# apollo4l register map
Vendor: Ambiq Micro; Series: Apollo; File version: 1.0
CPU: CM4 r1p0, little endian, MPU, FPU, I-cache, D-cache, VTOR, ITCM, DTCM, 3 interrupt priority bits, 0 interrupts
Registers are 32-bit, read-write, reset 0x0 unless marked. A register's access mark holds for its fields unless they carry their own. Offsets are from the block's base; [hi:lo] are bit positions; lines under a group give offsets from that group; {n}, {i} and the like mark numbered series; 'fields as' and 'values as' point back to an identical list.

## PWRCTRL — PWR Controller Register Bank
Base 0x40021000
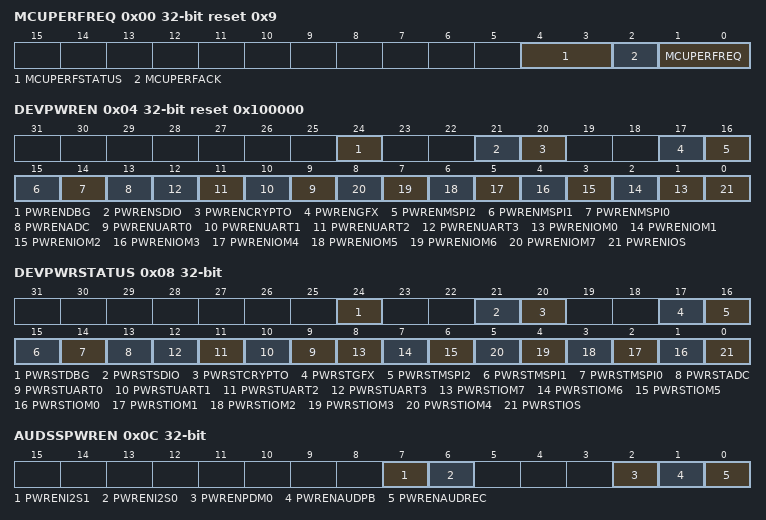
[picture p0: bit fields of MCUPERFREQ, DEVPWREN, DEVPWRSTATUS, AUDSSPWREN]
0x00 MCUPERFREQ reset 0x9 — This register provides the performance mode knobs for MCU. S/w should write the *PERFREQ field to desired mode and wait for the *PERFACK and check for the *PERFSTATUS. Some times system may not allow certain modes but *PERFACK should always follow *PERFREQ change.
  [4:3] MCUPERFSTATUS — MCU Performance mode request
    0=ULP (MCU is in ULP mode (freq=24MHz)); 1=LP (MCU is in LP mode (freq=96MHz)); 2=HP (MCU is in HP mode (freq=192MHz))
  [2] MCUPERFACK — Indicates the MCU performance status indicated in STATUS register is valid.
  [1:0] MCUPERFREQ — MCU Performance mode request
    0=ULP (MCU to be run in ULP mode (freq=24MHz)); 1=LP (MCU to be run in LP mode (freq=96MHz)); 2=HP (MCU to be run in HP mode (freq=192MHz))
0x04 DEVPWREN reset 0x100000 — This enables various peripherals power domains.
  [24] PWRENDBG — Powerup DBG power domain
    1=EN (Enable); 0=DIS (Disable)
  [21] PWRENSDIO — Power up SDIO controller
    1=EN (Power up SDIO); 0=DIS (Power down SDIO)
  [20] PWRENCRYPTO — Power up CRYPTO module
    1=EN (Power up CRYPTO); 0=DIS (Power down CRYPTO)
  [17] PWRENGFX — Power up GFX controller
    1=EN (Power up GFX); 0=DIS (Power down GFX)
  [16] PWRENMSPI2 — Power up MSPI Controller2
    1=EN (Power up MSPI2); 0=DIS (Power down MSPI2)
  [15] PWRENMSPI1 — Power up MSPI Controller1
    1=EN (Power up MSPI1); 0=DIS (Power down MSPI1)
  [14] PWRENMSPI0 — Power up MSPI Controller0
    1=EN (Power up MSPI0); 0=DIS (Power down MSPI0)
  [13] PWRENADC — Power up ADC Digital Controller
    1=EN (Power up ADC); 0=DIS (Power Down ADC)
  [n+9] PWRENUART{n} (n=0..3) — Power up UART Controller {n}
    1=EN (Power up UART {n}); 0=DIS (Power down UART {n})
  [n+1] PWRENIOM{n} (n=0..7) — Power up IO Master {n}
    1=EN (Power up IO Master {n}); 0=DIS (Power down IO Master {n})
  [0] PWRENIOS — Power up IO Slave
    1=EN (Power up IO slave); 0=DIS (Power down IO slave)
0x08 DEVPWRSTATUS — This provides the power status for the peripheral device domains controlled through DEVPWREN register. Value of 1 means the device is powred up and ready to be used and 0 means its not powered up.
  [all] fields
    1=ON (Domain powered on); 0=OFF (Domain powered off)
  [24] PWRSTDBG — Power Status DBG subsystem
  [21] PWRSTSDIO — Power Status SDIO controller
  [20] PWRSTCRYPTO — Power Status CRYPTO module
  [17] PWRSTGFX — Power Status GFX controller
  [16] PWRSTMSPI2 — Power Status MSPI Controller2
  [15] PWRSTMSPI1 — Power Status MSPI Controller1
  [14] PWRSTMSPI0 — Power Status MSPI Controller0
  [13] PWRSTADC — Power Status ADC Digital Controller
  [n+9] PWRSTUART{n} (n=0..3) — Power Status UART Controller {n}
  [8] PWRSTIOM7 — Power Status IO Master 7
  [7] PWRSTIOM6 — Power Status IO Master 6
  [6] PWRSTIOM5 — Power Status IO Master 5
  [n+1] PWRSTIOM{n} (n=0..4) — Power status IO Master {n}
  [0] PWRSTIOS — Power status IO Slave
0x0C AUDSSPWREN — This enables various power domains in audio subsystem.
  [7] PWRENI2S1 — Power up audio subsystem legacy I2S1 domain. I2S1 domain must be disabled. I2S1 is not available in Apoll4L.
    1=EN (Power up I2S1); 0=DIS (Power down I2S1)
  [6] PWRENI2S0 — Power up audio subsystem I2S0 domain
    1=EN (Power up I2S0); 0=DIS (Power down I2S0)
  [2] PWRENPDM0 — Power up audio subsystem PDM0 domain
    1=EN (Power up PDM0); 0=DIS (Power down PDM0)
  [1] PWRENAUDPB — Power up Audio Playback
    1=EN (Power up AUDPB); 0=DIS (Power down AUDPB)
  [0] PWRENAUDREC — Power up Audio Record
    1=EN (Power up AUDREC); 0=DIS (Power down AUDREC)
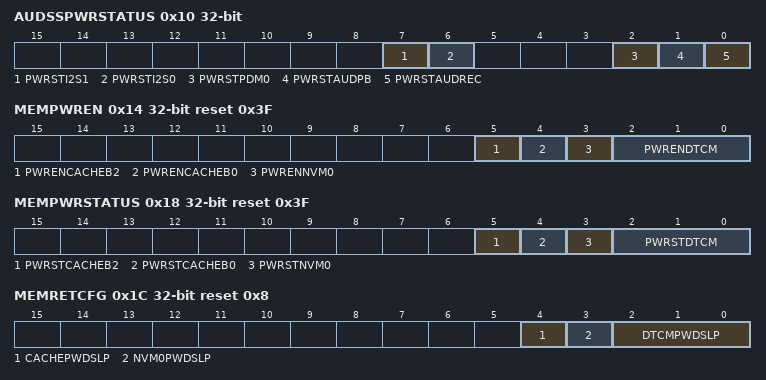
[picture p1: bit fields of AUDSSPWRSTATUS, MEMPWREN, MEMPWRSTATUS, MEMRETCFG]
0x10 AUDSSPWRSTATUS — This provides the power status for the peripheral domains controlled through AUDSSPWREN register. Value of 1 means the device is powred up and ready to be used and 0 means its not powered up.
  [all] fields
    1=ON (Domain powered on); 0=OFF (Domain powered off)
  [7] PWRSTI2S1 — Power Status audio subsystem legacy I2S1 domain. I2S1 is not available in Apoll4L.
  [6] PWRSTI2S0 — Power Status audio subsystem I2S0 domain
  [2] PWRSTPDM0 — Power Status audio subsystem PDM0 domain
  [1] PWRSTAUDPB — Power Status Audio Playback block
  [0] PWRSTAUDREC — Power Status Audio Record block
0x14 MEMPWREN reset 0x3F — This register enables the individual banks for the memories. When set, power will be enabled to the banks. This register works in conjunction with the MEMRETCFG register. If this register is not set, then power will always be disabled to the memory bank.
  [5] PWRENCACHEB2 — Power up Cache Bank 2. This works in conjunction with Cache enable from flash_cache module. To power up cache bank2, cache has to be enabled and this bit has to be set.
    1=EN (Power up Cache Bank 2); 0=DIS (Power down Cache Bank 2)
  [4] PWRENCACHEB0 — Power up Cache Bank 0. This works in conjunction with Cache enable from flash_cache module. To power up cache bank0, cache has to be enabled and this bit has to be set.
    1=EN (Power up Cache Bank 0); 0=DIS (Power down Cache Bank 0)
  [3] PWRENNVM0 — Power up NVM0
    1=EN (Power up NVM0); 0=DIS (Power down NVM0)
  [2:0] PWRENDTCM — Power up DTCM
    0=NONE (Do not enable power to any DTCMs); 1=TCM32K (Power ON only lower 32k); 3=TCM128K (Power ON only lower 128k); 7=TCM384K (Power ON 384k)
0x18 MEMPWRSTATUS reset 0x3F — It provides the power status for all the memory banks including- caches, nvm (0 and 1) and all the SRAM groups. The status here should reflect the enable provided by the MEMPWREN register. There may be a lag time between setting the bits in MEMPWREN register and MEMPWRSTATUS register, due to the need to cycle the power gate and isolation seqeunces to the memory banks.
  [5] PWRSTCACHEB2 — This bit is 1 if power is supplied to Cache Bank 2
  [4] PWRSTCACHEB0 — This bit is 1 if power is supplied to Cache Bank 0
  [3] PWRSTNVM0 — This bit is 1 if power is supplied to NVM 0
  [2:0] PWRSTDTCM — Power status for DTCM. Each bit corresponds to one of the TCMs. bit0=DTCM0_0, bit1=DTCM0_1, bit2=DTCM1.
    0=NONE (Do not enable power to any DTCMs); 1=TCM32K (Only lower 32k is powered up); 3=TCM128K (Only lower 128k is powered up); 7=TCM384K (All 384k is powered up)
0x1C MEMRETCFG reset 0x8 — This controls the power down of the SRAM banks in deep sleep mode. If this is set, then the power for that SRAM bank will be gated when the core goes into deep sleep. Upon wake, the data within the SRAMs will be erased. If this is not set, retention voltage will be applied to the SRAM bank when the core goes into deep sleep. Upon wake, the data within the SRAMs are retained. Do not set this if the SRAM bank is used as the target for DMA transfer while CPU in deepsleep.
  [4] CACHEPWDSLP — power down cache in deep sleep
    1=EN (Power down cache in deep sleep); 0=DIS (Retain cache in deep sleep)
  [3] NVM0PWDSLP — Powerdown NVM0 in deep sleep
    1=EN (NVM0 is powered down during deepsleep); 0=DIS (NVM0 is kept powered on during deepsleep)
  [2:0] DTCMPWDSLP — power down DTCM in deep sleep
    0=NONE (All DTCM retained); 1=GROUP0DTCM0 (Group0_DTCM0 powered down in deep sleep (0KB-32KB)); 2=GROUP0DTCM1 (Group0_DTCM1 powered down in deep sleep (32KB-128KB)); 3=GROUP0 (Both DTCMs in group0 are powered down in deep sleep (0KB-128KB)); 6=ALLBUTGROUP0DTCM0 (Group1 and Group0_DTCM1 are powered down in deep sleep (32KB-384KB)); 4=GROUP1 (Group1 DTCM powered down in deep sleep (128KB-384KB)); 7=ALL (All DTCMs powered down in deep sleep (0KB-384KB))
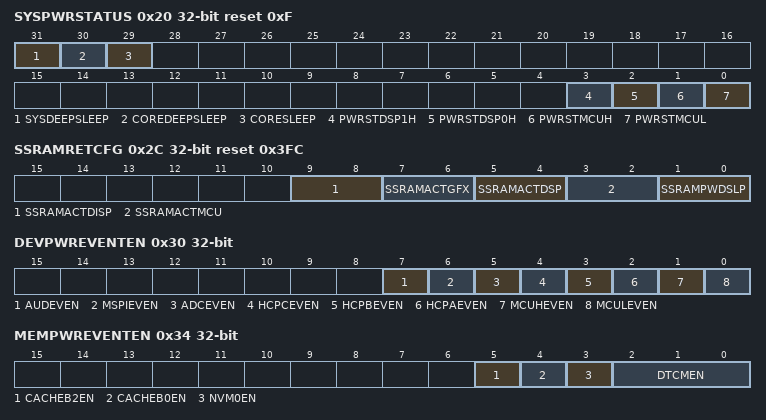
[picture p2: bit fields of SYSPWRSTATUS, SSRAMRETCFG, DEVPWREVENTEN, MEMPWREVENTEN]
0x20 SYSPWRSTATUS reset 0xF — Power ON Status for domains that are not part of devpwrstatus or mempwrstatus
  [31] SYSDEEPSLEEP — Indicates all device domains powered down and MCU entered DEEPSLEEP state since it was last cleared. Write 1 to to clear it.
  [30] COREDEEPSLEEP — Indicates MCU entered DEEPSLEEP state since it was last cleared. Write 1 to to clear it.
  [29] CORESLEEP — Indicates MCU entered SLEEP state since it was last cleared. Write 1 to to clear it.
  [3] PWRSTDSP1H — Power Domain status for DSP1H
  [2] PWRSTDSP0H — Power Domain status for DSP0H
  [1] PWRSTMCUH — Power Domain status for MCUH
  [0] PWRSTMCUL — Power Domain status for MCUL
0x24 SSRAMPWREN — This register enables the individual banks for the memories. When set, power will be enabled to the banks. This register works in conjunction with the SSRAMRETCFG register. If this register is not set, then power will always be disabled to the memory bank.
  [1:0] PWRENSSRAM — Power up SRAM groups
    0=NONE (Do not power ON any of the SRAM banks); 1=GROUP0 (Power ON only SRAM0 group (lower 1M)); 2=GROUP1 (Power ON only SRAM1 group (upper 1M)); 3=ALL (All shared SRAM banks (SSRAM0 1M + SSRAM1 1M) powered ON)
0x28 SSRAMPWRST reset 0x3 — It provides the power status for shared sram banks. The status here should reflect the enable provided by the SSRAMPWREN register.
  [1:0] SSRAMPWRST — Each bit corresponds to one 1M SSRAM group. Power Status- 1:ON, 0:OFF See SSRAMPWREN PWRENSSRAM for bit mapping. For example, a value of 2 in this field would mean that SSRAM1 is powered up and SSRAM0 is powered down.
0x2C SSRAMRETCFG reset 0x3FC — This controls the power down of the Shared SRAM banks in deep sleep mode. If this is set, then the power for that SRAM bank will be gated when the core goes into deep sleep. Upon wake, the data within the SRAMs will be erased. If this is not set, retention voltage will be applied to the SRAM bank when none of the CPU agents are in powered up and active mode. Do not set this if the SRAM bank is used as the target for DMA transfer while CPU in deepsleep.
  [9:8] SSRAMACTDISP — Keep the memory domain active based on DISP state. Each bit corresponds to a domain. 1: Keep SRAM active 0: Powerup on demand (i.e. when DISP is powered up)
  [7:6] SSRAMACTGFX — Keep the memory domain active based on GFX state. Each bit corresponds to a domain. 1: Keep SRAM active 0: Powerup on demand (i.e. when GFX is powered up)
  [5:4] SSRAMACTDSP — Keep the memory domain active based on DSP state. Each bit corresponds to a domain. 1: Keep SRAM active 0: Powerup on demand (i.e. when DSP is powered up)
  [3:2] SSRAMACTMCU — Keep the memory domain active based on MCU state. Each bit corresponds to a domain. 1: Keep SRAM active 0: Wakeup on demand (i.e. when MCU is powered up)
  [1:0] SSRAMPWDSLP — Selects which shared SRAM banks are powered down in deep sleep mode, causing the contents of the bank to be lost.
    0=NONE (All banks retained); 1=GROUP0 (Power down only SRAM group0); 2=GROUP1 (Power down only SRAM group1); 3=ALL (All shared SRAM banks powered down)
0x30 DEVPWREVENTEN — This register controls which feature trigger will result in an event to the CPU. It includes all the power on status for the core domains. If any bits are set, then if the domain is turned on, it will result in an event to the ARM core.
  [7] AUDEVEN — Control AUD power-on status event
    1=EN (Enable AUD power-on status event); 0=DIS (Disable AUD power-on status event)
  [6] MSPIEVEN — Control MSPI power-on status event
    1=EN (Enable MSPI power-on status event); 0=DIS (Disable MSPI power-on status event)
  [5] ADCEVEN — Control ADC power-on status event
    1=EN (Enable ADC power-on status event); 0=DIS (Disable ADC power-on status event)
  [4] HCPCEVEN — Control HCPC power-on status event
    1=EN (Enable HCPC power-on status event); 0=DIS (Disable HCPC power-on status event)
  [3] HCPBEVEN — Control HCPB power-on status event
    1=EN (Enable HCPB power-on status event); 0=DIS (Disable HCPB power-on status event)
  [2] HCPAEVEN — Control HCPA power-on status event
    1=EN (Enable HCPA power-on status event); 0=DIS (Disable HCPA power-on status event)
  [1] MCUHEVEN — Control MCUH power-on status event
    1=EN (Enable MCHU power-on status event); 0=DIS (Disable MCUH power-on status event)
  [0] MCULEVEN — Control MCUL power-on status event
    1=EN (Enable MCUL power-on status event); 0=DIS (Disable MCUL power-on status event)
0x34 MEMPWREVENTEN — This register controls which power enable for the memories will result in an event to the CPU. It includes all the power on status for the memory domains. If any bits are set, then if the domain is turned on, it will result in an event to the ARM core.
  [5] CACHEB2EN — Control CACHEB2 power-on status event
    1=EN (Enable CACHE BANK 2 status event); 0=DIS (Disable CACHE BANK 2 status event)
  [4] CACHEB0EN — Control CACHE BANK 0 power-on status event
    1=EN (Enable CACHE BANK 0 status event); 0=DIS (Disable CACHE BANK 0 status event)
  [3] NVM0EN — Control NVM power-on status event
    1=EN (Enable NVM status event); 0=DIS (Disables NVM status event)
  [2:0] DTCMEN — Enable DTCM power-on status event
    0=NONE (Do not enable DTCM power-on status event); 1=GROUP0DTCM0EN (Enable GROUP0_DTCM0 power on status event); 2=GROUP0DTCM1EN (Enable GROUP0_DTCM1 power on status event); 3=GROUP0EN (Enable DTCMs in group0 power on status event); 4=GROUP1EN (Enable DTCMs in group1 power on status event); 7=ALL (Enable all DTCM power on status event)
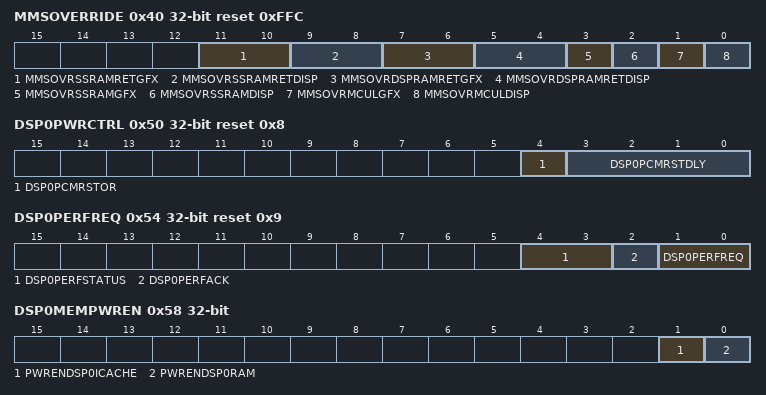
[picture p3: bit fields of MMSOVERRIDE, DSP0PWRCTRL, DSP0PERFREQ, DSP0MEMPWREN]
0x40 MMSOVERRIDE reset 0xFFC — Power domain behavior overrides related to MMS ( Multimedia System ).
  [11:10] MMSOVRSSRAMRETGFX — If set, retention equation doesn't consider GFX. Each bit corresponds to a domain.
    1=ALWAYSON (When PD_GFX is off, retention is always okay for PD_GFX domain.); 0=PGSTATE (When PD_GFX is off, retention is okay based on the state of PD_GFX domain and SSRAMRETCFG.)
  [9:8] MMSOVRSSRAMRETDISP — If set, retention equation doesn't consider DISP. Each bit corresponds to a domain.
    1=ALWAYSON (When PD_DISP is off, retention is always okay for PD_DISP domain.); 0=PGSTATE (When PD_DISP is off, retention is okay based on the state of PD_DISP domain and SSRAMRETCFG.)
  [7:6] MMSOVRDSPRAMRETGFX — If set, retention equation doesn't consider GFX. Each bit corresponds to a domain.
    1=ALWAYSON (When PD_GFX is off, retention is always okay for PD_GFX domain.); 0=PGSTATE (When PD_GFX is off, retention is okay based on the state of PD_GFX domain and DSP[1|0]MEMRETCFG.)
  [5:4] MMSOVRDSPRAMRETDISP — If set, retention equation doesn't consider DISP. Each bit corresponds to a domain.
    1=ALWAYSON (When PD_DISP is off, retention is always okay for PD_DISP domain.); 0=PGSTATE (When PD_DISP is off, retention is okay based on the state of PD_DISP domain and DSP[1|0]MEMRETCFG.)
  [3] MMSOVRSSRAMGFX — MMS override for SSRAM power state by PD_GFX power setting.
    1=NOGFX (SSRAM power state is not affected by PD_GFX setting.); 0=PD_GFX (SSRAM power state set by SSRAMPWREN_PWRENSSRAM is overridden by PD_GFX setting.)
  [2] MMSOVRSSRAMDISP — MMS override for SSRAM power state by PD_DISP power setting.
    1=NODISP (SSRAM power state is not affected by PD_DISP setting.); 0=PD_DISP (SSRAM power state set by SSRAMPWREN_PWRENSSRAM is overridden by PD_DISP setting.)
  [1] MMSOVRMCULGFX — MMS override for MCUL on by PD_GFX setting.
    0=MCULON (When PD_GFX is on, MCUL is on.); 1=MCULOFF (When PD_GFX is on, MCUL is still off.)
  [0] MMSOVRMCULDISP — MMS override for MCUL on by PD_DISP setting.
    0=MCULON (When PD_DISP is on, MCUL is on.); 1=MCULOFF (When PD_DISP is on, MCUL is still off.)
0x50 DSP0PWRCTRL reset 0x8 — Power and RST controls for DSP0
  [4] DSP0PCMRSTOR — PCM Reset override. If this is disabled, then h/w will handle the de-assertion of pcm reset.
    1=EN (Keep DSP0 PCM in Reset); 0=DIS (Remove DSP0 PCM Reset override)
  [3:0] DSP0PCMRSTDLY — PCM Reset delay in number of 24MHz clocks.
0x54 DSP0PERFREQ reset 0x9 — This register provides the performance mode knobs for DSP0. S/w should write the *PERFREQ field to desired mode and wait for the *PERFACK and check for the *PERFSTATUS. Some times system may not allow certain modes but *PERFACK should always follow *PERFREQ change.
  [4:3] DSP0PERFSTATUS — DSP0 Performance mode request
    0=ULP (DSP0 is in ULP mode (freq=48MHz)); 1=LP (DSP0 is in LP mode (freq=192MHz)); 2=HP (DSP0 is in HP mode (freq=384MHz))
  [2] DSP0PERFACK — Indicates the DSP0 performance status indicated in STATUS register is valid.
  [1:0] DSP0PERFREQ — DSP0 Performance mode request
    0=ULP (DSP0 to be run in ULP mode (freq=48MHz)); 1=LP (DSP0 to be run in LP mode (freq=192MHz)); 2=HP (DSP0 to be run in HP mode (freq=384MHz))
0x58 DSP0MEMPWREN — This register enables the individual banks for the memories. When set, power will be enabled to the banks. This register works in conjunction with the DSP0MEMRETCFG register when DSP0 is OFF.
  [1] PWRENDSP0ICACHE — Power up DSP0 ICACHE banks
    0=OFF (Do not power up ICACHE); 1=ON (Power up ICACHE)
  [0] PWRENDSP0RAM — Power up DSP0 IRAM and DRAM
    0=OFF (Do not power ON any of the IRAM/DRAM); 1=ON (Power up all IRAM (128K) and DRAM (256K))
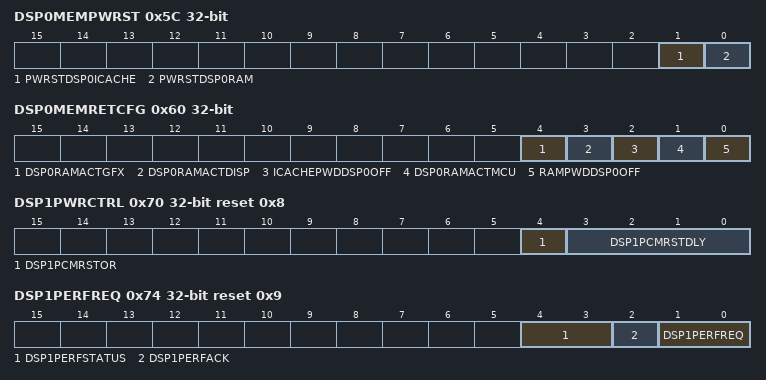
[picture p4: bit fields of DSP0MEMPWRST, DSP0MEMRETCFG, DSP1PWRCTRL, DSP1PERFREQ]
0x5C DSP0MEMPWRST — It provides the power status for all the memories of DSP0 subsystem
  [1] PWRSTDSP0ICACHE — Power Status- 1:ON, 0:OFF
  [0] PWRSTDSP0RAM — Status- 1:ON, 0:OFF
0x60 DSP0MEMRETCFG — This controls the power down of the DRAM/IRAM/CACHE banks when DSP0 is powered off. If this is set, then the power for that corresponding SRAM bank will be gated when the DSP0 is powered off and data is erased. If this is not set, retention voltage will be applied when DSP0 is powered off. Do not set this if the SRAM bank is used as the target for DMA transfer while DSP0 is powered off.
  [4] DSP0RAMACTGFX — Keep the memory domain active based on GFX state.
    0=WAKEONDEMAND (Wakeup on demand); 1=ACT (Keep RAMs active irrespective of GFX state)
  [3] DSP0RAMACTDISP — Keep the memory domain active based on DISP state.
    0=WAKEONDEMAND (Wakeup on demand); 1=ACT (Keep RAMs active irrespective of DISP state)
  [2] ICACHEPWDDSP0OFF — ICACHE is powered down when DSP0 is switched off, causing the contents of the bank to be lost.
    0=RET (ICACHE retained); 1=PWD (Power down ICACHE)
  [1] DSP0RAMACTMCU — Keep the memory domain active based on MCU state.
    0=WAKEONDEMAND (Wakeup on demand); 1=ACT (Keep RAMs active irrespective of MCU state)
  [0] RAMPWDDSP0OFF — IRAM/DRAM banks are powered down when DSP0 is switched off, causing the contents of the bank to be lost.
    0=RET (IRAM and DRAM retained); 1=PWD (Power down all IRAM and DRAM)
0x70 DSP1PWRCTRL reset 0x8 — Power and RST controls for DSP1
  [4] DSP1PCMRSTOR — PCM Reset override. If this is disabled, then h/w will handle the de-assertion of pcm reset.
    1=EN (Keep DSP1 PCM in Reset); 0=DIS (Remove DSP1 PCM Reset override)
  [3:0] DSP1PCMRSTDLY — PCM Reset delay in number of 24MHz clocks.
0x74 DSP1PERFREQ reset 0x9 — This register provides the performance mode knobs for DSP1. S/w should write the *PERFREQ field to desired mode and wait for the *PERFACK and check for the *PERFSTATUS. Some times system may not allow certain modes but *PERFACK should always follow *PERFREQ change.
  [4:3] DSP1PERFSTATUS — DSP1 Performance mode request
    0=ULP (DSP1 is in ULP mode (freq=48MHz)); 1=LP (DSP1 is in LP mode (freq=192MHz)); 2=HP (DSP1 is in HP mode (freq=384MHz))
  [2] DSP1PERFACK — Indicates the DSP1 performance status indicated in STATUS register is valid.
  [1:0] DSP1PERFREQ — DSP1 Performance mode request
    0=ULP (DSP1 to be run in ULP mode (freq=48MHz)); 1=LP (DSP1 to be run in LP mode (freq=192MHz)); 2=HP (DSP1 to be run in HP mode (freq=384MHz))
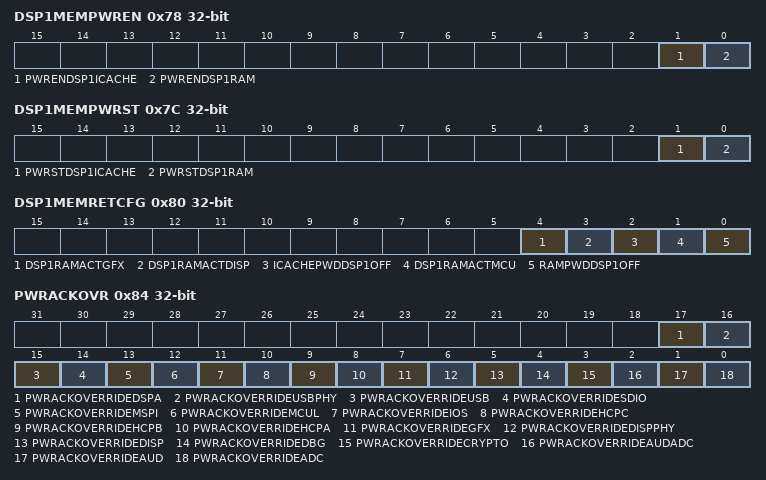
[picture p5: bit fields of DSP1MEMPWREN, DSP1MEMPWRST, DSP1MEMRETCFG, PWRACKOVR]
0x78 DSP1MEMPWREN — This register enables the individual banks for the memories. When set, power will be enabled to the banks. This register works in conjunction with the DSP1MEMRETCFG register when DSP1 is OFF.
  [1] PWRENDSP1ICACHE — Power up DSP1 ICACHE banks
    0=OFF (Do not power up ICACHE); 1=ON (Power up ICACHE)
  [0] PWRENDSP1RAM — Power up DSP1 IRAM and DRAM
    0=OFF (Do not power ON any of the IRAM/DRAM); 1=ON (Power up all IRAM (32K) and DRAM (64K))
0x7C DSP1MEMPWRST — It provides the power status for all the memories of DSP1 subsystem
  [1] PWRSTDSP1ICACHE — Power Status- 1:ON, 0:OFF
  [0] PWRSTDSP1RAM — Status- 1:ON, 0:OFF
0x80 DSP1MEMRETCFG — This controls the power down of the DRAM/IRAM/CACHE banks when DSP1 is powered off. If this is set, then the power for that corresponding SRAM bank will be gated when the DSP1 is powered off and data is erased. If this is not set, retention voltage will be applied when DSP1 is powered off. Do not set this if the SRAM bank is used as the target for DMA transfer while DSP1 is powered off.
  [4] DSP1RAMACTGFX — Keep the memory domain active based on GFX state.
    values as DSP0MEMRETCFG.DSP0RAMACTGFX
  [3] DSP1RAMACTDISP — Keep the memory domain active based on DISP state.
    values as DSP0MEMRETCFG.DSP0RAMACTDISP
  [2] ICACHEPWDDSP1OFF — ICACHE is powered down when DSP1 is switched off, causing the contents of the bank to be lost.
    0=RET (ICACHE retained); 1=PWD (Power down ICACHE)
  [1] DSP1RAMACTMCU — Keep the memory domain active based on MCU state.
    values as DSP0MEMRETCFG.DSP0RAMACTMCU
  [0] RAMPWDDSP1OFF — IRAM/DRAM banks are powered down when DSP1 is switched off, causing the contents of the bank to be lost.
    values as DSP0MEMRETCFG.RAMPWDDSP0OFF
0x84 PWRACKOVR — This register contains override bit fields for various power domain power switch acknowledge notification. As a part of power up sequnce, Power controller will look for power switch ack to advance power up sequence. It is possible for power controller to be a forever wait state in case of a unforeseen HW bug. This register defines a bit fileds to work around if needed in such a situation. The default behavior is to use HW power switch ack. Software can set it to override this feature for each power switch.
  [all] fields
    0=DEFAULT (Hardware generates Power switch ack); 1=SWOVRRIDE (Software override or defeaure mode. Will bypass HW generated power ack)
  [17] PWRACKOVERRIDEDSPA — Power switch acknowledgement override from Power switch to power control ST MC
  [16] PWRACKOVERRIDEUSBPHY — Power switch acknowledgement override from Power switch to power control ST MC
  [15] PWRACKOVERRIDEUSB — Power switch acknowledgement override from Power switch to power control ST MC
  [14] PWRACKOVERRIDESDIO — Power switch acknowledgement override from Power switch to power control ST MC
  [13] PWRACKOVERRIDEMSPI — Power switch acknowledgement override from Power switch to power control ST MC
  [12] PWRACKOVERRIDEMCUL — Power switch acknowledgement override from Power switch to power control ST MC
  [11] PWRACKOVERRIDEIOS — Power switch acknowledgement override from Power switch to power control ST MC
  [10] PWRACKOVERRIDEHCPC — Power switch acknowledgement override from Power switch to power control ST MC
  [9] PWRACKOVERRIDEHCPB — Power switch acknowledgement override from Power switch to power control ST MC
  [8] PWRACKOVERRIDEHCPA — Power switch acknowledgement override from Power switch to power control ST MC
  [7] PWRACKOVERRIDEGFX — Power switch acknowledgement override from Power switch to power control ST MC
  [6] PWRACKOVERRIDEDISPPHY — Power switch acknowledgement override from Power switch to power control ST MC
  [5] PWRACKOVERRIDEDISP — Power switch acknowledgement override from Power switch to power control ST MC
  [4] PWRACKOVERRIDEDBG — Power switch acknowledgement override from Power switch to power control ST MC
  [3] PWRACKOVERRIDECRYPTO — Power switch acknowledgement override from Power switch to power control ST MC
  [2] PWRACKOVERRIDEAUDADC — Power switch acknowledgement override from Power switch to power control ST MC
  [1] PWRACKOVERRIDEAUD — Power switch acknowledgement override from Power switch to power control ST MC
  [0] PWRACKOVERRIDEADC — Power switch acknowledgement override from Power switch to power control ST MC
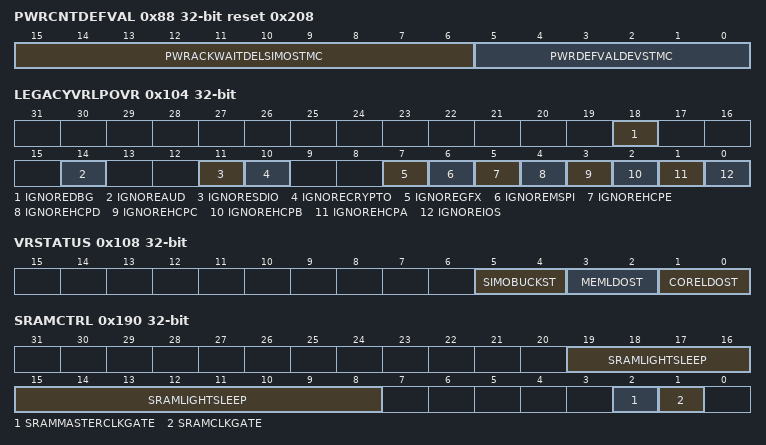
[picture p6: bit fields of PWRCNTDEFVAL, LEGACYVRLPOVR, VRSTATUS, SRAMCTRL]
0x88 PWRCNTDEFVAL reset 0x208 — This register contains programmble delay values for various state michines. Fields contain dev st machine default value, SIMOBUCK state machine wait delay counter etc.
  [15:6] PWRACKWAITDELSIMOSTMC — Default counter max for buck ST MC
  [5:0] PWRDEFVALDEVSTMC — Default count max value for dev ST MC
0x100 VRCTRL — This register includes additional debug control bits. This is an internal Ambiq-only register. Customers should not attempt to change this or else functionality cannot be guaranteed.
  [0] SIMOBUCKEN — Enables and Selects the SIMO Buck as the supply for the low-voltage power domains. It takes the initial value from the bit set in Customer INFO space.
    1=EN (Enable the SIMO Buck); 0=DIS (Disable the SIMO Buck)
0x104 LEGACYVRLPOVR — When an override is set for a power domain, VR logic will ignore that power domain state in making a decision to go into lp state.
  [18] IGNOREDBG, [14] IGNOREAUD, [11] IGNORESDIO, [10] IGNORECRYPTO, [7] IGNOREGFX, [6] IGNOREMSPI, [5] IGNOREHCPE, [4] IGNOREHCPD, [3] IGNOREHCPC, [2] IGNOREHCPB, [1] IGNOREHCPA, [0] IGNOREIOS
0x108 VRSTATUS — Provides BUCK and LDOs status.
  [5:4] SIMOBUCKST — Indicates SIMO BUCK status. bit[1] indicates ON/OFF and bit[0] indicates ACT/LP
    0=OFF (Indicates the the SIMO BUCK is OFF.); 2=LP (Indicates the the SIMO BUCK is ON and in LP mode.); 3=ACT (Indicates the the SIMO BUCK is ON and in ACT mode.)
  [3:2] MEMLDOST — Indicates MEMLDO status. bit[1] indicates ON/OFF and bit[0] indicates ACT/LP.
    0=OFF (Indicates the the MEMLDO is OFF.); 2=LP (Indicates the the MEMLDO is ON and in LP mode.); 3=ACT (Indicates the the MEMLDO is ON and in ACT mode.)
  [1:0] CORELDOST — Indicates CORELDO status. bit[1] indicates ON/OFF and bit[0] indicates ACT/LP.
    0=OFF (Indicates the the CORELDO is OFF.); 2=LP (Indicates the the CORELDO is ON and in LP mode.); 3=ACT (Indicates the the CORELDO is ON and in ACT mode.)
0x190 SRAMCTRL — This register provides additional fine-tune power management controls for the SRAMs and the SRAM controller. This includes enabling light sleep for the SRAM and TCM banks, and clock gating for reduced dynamic power.
  [19:8] SRAMLIGHTSLEEP — Light Sleep enable for each TCM/SRAM bank. When 1, corresponding bank will be put into light sleep. For optimal power, banks should be put into light sleep while the system is active but the bank has minimal or no accesses.
    0xFFF=ALL (Enable LIGHT SLEEP for ALL SRAMs); 0=DIS (Disables LIGHT SLEEP for ALL SRAMs)
  [2] SRAMMASTERCLKGATE — This bit is 1 when the master clock gate is enabled (top-level clock gate for entire SRAM block)
    1=EN (Enable Master SRAM Clock Gate); 0=DIS (Disables Master SRAM Clock Gating)
  [1] SRAMCLKGATE — This bit is 1 if clock gating is allowed for individual system SRAMs
    1=EN (Enable Individual SRAM Clock Gating); 0=DIS (Disables Individual SRAM Clock Gating)
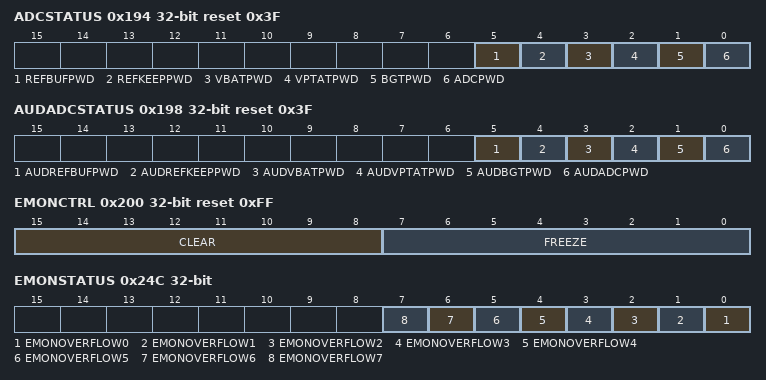
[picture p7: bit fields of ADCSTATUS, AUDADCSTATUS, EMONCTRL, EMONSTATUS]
0x194 ADCSTATUS reset 0x3F — This provides the power status for various blocks within the ADC. These status comes directly from the ADC module and is captured through this interface.
  [5] REFBUFPWD — This bit indicates that the ADC REFBUF is powered down
  [4] REFKEEPPWD — This bit indicates that the ADC REFKEEP is powered down
  [3] VBATPWD — This bit indicates that the ADC VBAT resistor divider is powered down
  [2] VPTATPWD — This bit indicates that the ADC temperature sensor input buffer is powered down
  [1] BGTPWD — This bit indicates that the ADC Band Gap is powered down
  [0] ADCPWD — This bit indicates that the ADC is powered down
0x198 AUDADCSTATUS reset 0x3F — This provides the power status for various blocks within the audio ADC. These status comes directly from the audio ADC module and is captured through this interface.
  [5] AUDREFBUFPWD — This bit indicates that the ADC REFBUF is powered down
  [4] AUDREFKEEPPWD — This bit indicates that the ADC REFKEEP is powered down
  [3] AUDVBATPWD — This bit indicates that the ADC VBAT resistor divider is powered down
  [2] AUDVPTATPWD — This bit indicates that the ADC temperature sensor input buffer is powered down
  [1] AUDBGTPWD — This bit indicates that the ADC Band Gap is powered down
  [0] AUDADCPWD — This bit indicates that the ADC is powered down
0x200 EMONCTRL reset 0xFF — Controls each of the energy monitor conuters
  [15:8] CLEAR — Clear the counter. Each bit corresponds to a counter. 0: Let the counter run run on its input clk. 1: Clear the counter
  [7:0] FREEZE — Freeze the counter. Each bit corresponds to a counter. 0: Let the counter run. 1: Stop the counter.
{0x204+4i} EMONCFG{i} (i=0..7) — The counter increments when the counter is enabled and the mode selected here matches the power mode.
  [7:0] EMONSEL{i} — Power modes for incrementing the counter
    0=NEVER (Never increment the counter); 1=ALWAYS (Always increment the counter); 2=MCUSLEEP (Increment the counter for MCU sleep mode); 3=MCUDEEPSLEEP (Increment the counter for MCU deepsleep mode); 4=DSP0ON (Increment the counter for DSP0 active mode); 5=DSP1ON (Increment the counter for DSP1 active mode); 6=ADCON (Increment the counter when ADC is powered on); 7=AUDPBON (Increment the counter when AUDPB is powered on); 8=AUDRECON (Increment the counter when AUDREC is powered on); 9=I2S0ON (Increment the counter when I2S0 is powered on); 10=PDM0ON (Increment the counter when PDM0 is powered on); 11=CRYPTOON (Increment the counter when CRYPTO is powered on); 12=DBGON (Increment the counter when DBG is powered on); 13=DSPAON (Increment the counter when DSPA is powered on); 14=GFXON (Increment the counter when GFX is powered on); {v}=UART{v-15}ON (Increment the counter when UART{v-15} is powered on) (v=15..18); {v}=IOM{v-19}ON (Increment the counter when IOM{v-19} is powered on) (v=19..22); {v}=IOM{v-21}ON (Increment the counter when IOM{v-21} is powered on) (v=25..28); 29=IOSON (Increment the counter when IOS is powered on); 30=MSPI0ON (Increment the counter when MSPI0 is powered on); 31=MSPI1ON (Increment the counter when MSPI1 is powered on); 32=MSPI2ON (Increment the counter when MSPI2 is powered on); 33=SDIOON (Increment the counter when SDIO is powered on)
{0x228+4i} EMONCOUNT{i} (i=0..7) — Energy Monitor count value for counter {i}
  [31:0] EMONCOUNT{i} — Energy Monitor count value counter {i}
0x24C EMONSTATUS — Energy Monitor status
  [n] EMONOVERFLOW{n} (n=0..7) — Energy Monitor counter{n} overflow
